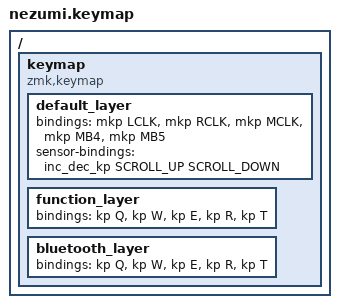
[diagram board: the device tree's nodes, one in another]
/*
 * Copyright (c) 2021 The ZMK Contributors
 *
 * SPDX-License-Identifier: MIT
 */

#include <behaviors.dtsi>
#include <dt-bindings/zmk/keys.h>
#include <dt-bindings/zmk/bt.h>
#include <dt-bindings/zmk/outputs.h>
#include <dt-bindings/zmk/mouse.h>

#define DEFAULT    0
#define FUNCTION   1
#define BLUETOOTH  2

/ {
    keymap {
        compatible = "zmk,keymap";

        default_layer {
                bindings = <
                    &mkp LCLK &mkp RCLK &mkp MCLK &mkp MB4 &mkp MB5
                >;
                sensor-bindings = <&inc_dec_kp SCROLL_UP SCROLL_DOWN >;
                };

        function_layer {
                bindings = <
                    &kp Q &kp W &kp E  &kp R     &kp T>;
                };

        bluetooth_layer {
                bindings = <
                    &kp Q &kp W &kp E  &kp R     &kp T>;
                };
    };
};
